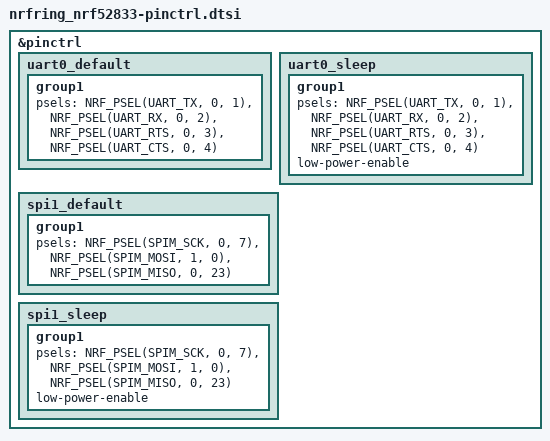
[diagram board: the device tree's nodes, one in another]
/*
 * Copyright (c) 2023 Aedan Cullen <aedan@aedancullen.com>
 * Copyright (c) 2022 Nordic Semiconductor
 * SPDX-License-Identifier: Apache-2.0
 */

&pinctrl {
	uart0_default: uart0_default {
		group1 {
			psels = <NRF_PSEL(UART_TX, 0, 1)>,
				<NRF_PSEL(UART_RX, 0, 2)>,
				<NRF_PSEL(UART_RTS, 0, 3)>,
				<NRF_PSEL(UART_CTS, 0, 4)>;
		};
	};

	uart0_sleep: uart0_sleep {
		group1 {
			psels = <NRF_PSEL(UART_TX, 0, 1)>,
				<NRF_PSEL(UART_RX, 0, 2)>,
				<NRF_PSEL(UART_RTS, 0, 3)>,
				<NRF_PSEL(UART_CTS, 0, 4)>;
			low-power-enable;
		};
	};

	spi1_default: spi1_default {
		group1 {
			psels = <NRF_PSEL(SPIM_SCK, 0, 7)>,
				<NRF_PSEL(SPIM_MOSI, 1, 0)>,
				<NRF_PSEL(SPIM_MISO, 0, 23)>;
		};
	};

	spi1_sleep: spi1_sleep {
		group1 {
			psels = <NRF_PSEL(SPIM_SCK, 0, 7)>,
				<NRF_PSEL(SPIM_MOSI, 1, 0)>,
				<NRF_PSEL(SPIM_MISO, 0, 23)>;
			low-power-enable;
		};
	};

};
